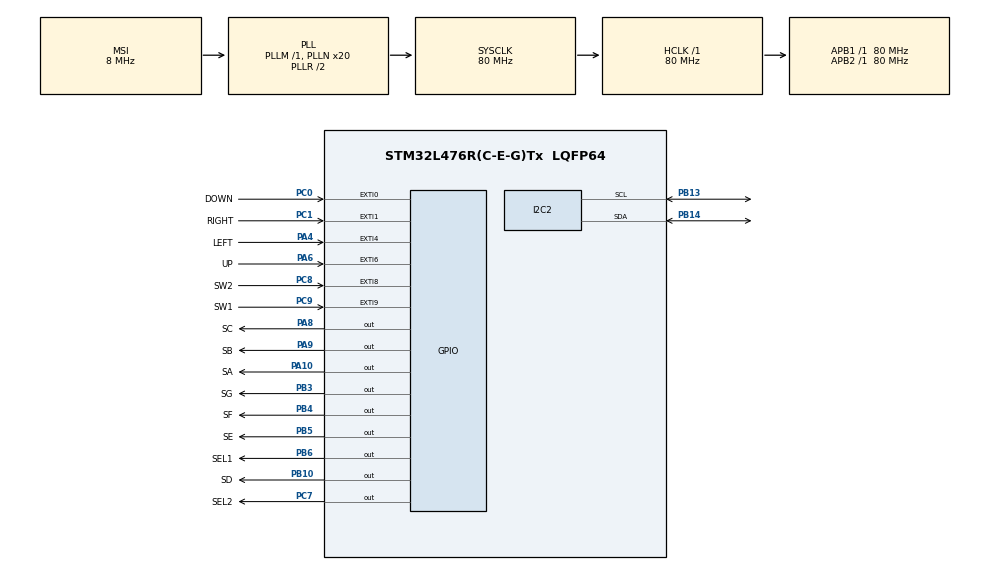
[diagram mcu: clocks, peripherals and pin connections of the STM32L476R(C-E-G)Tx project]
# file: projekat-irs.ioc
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FREERTOS.Tasks01=defaultTask,0,128,StartDefaultTask,Default,NULL,Dynamic,NULL,NULL
FREERTOS.configUSE_TIMERS=1
I2C2.Timing=0x10909CEC
Mcu.Family=STM32L4
Mcu.Name=STM32L476R(C-E-G)Tx
Mcu.Package=LQFP64
NVIC.EXTI0_IRQn=true\:5\:0\:false\:false\:true\:true\:true\:true\:true
NVIC.EXTI1_IRQn=true\:5\:0\:false\:false\:true\:true\:true\:true\:true
NVIC.EXTI4_IRQn=true\:5\:0\:false\:false\:true\:true\:true\:true\:true
NVIC.EXTI9_5_IRQn=true\:5\:0\:false\:false\:true\:false\:true\:true\:true
NVIC.PriorityGroup=NVIC_PRIORITYGROUP_4
PA10.GPIO_Label=SA
PA10.Signal=GPIO_Output
PA11.Signal=S_TIM1_CH4
PA4.GPIO_Label=LEFT
PA4.GPIO_ModeDefaultEXTI=GPIO_MODE_IT_FALLING
PA4.GPIO_PuPd=GPIO_PULLUP
PA4.Signal=GPXTI4
PA6.GPIO_Label=UP
PA6.GPIO_ModeDefaultEXTI=GPIO_MODE_IT_FALLING
PA6.GPIO_PuPd=GPIO_PULLUP
PA6.Signal=GPXTI6
PA8.GPIO_Label=SC
PA8.Signal=GPIO_Output
PA9.GPIO_Label=SB
PA9.Signal=GPIO_Output
PB10.GPIO_Label=SD
PB10.Signal=GPIO_Output
PB13.Mode=I2C
PB13.Signal=I2C2_SCL
PB14.Mode=I2C
PB14.Signal=I2C2_SDA
PB3\ (JTDO-TRACESWO).GPIO_Label=SG
PB3\ (JTDO-TRACESWO).Signal=GPIO_Output
PB4\ (NJTRST).GPIO_Label=SF
PB4\ (NJTRST).Signal=GPIO_Output
PB5.GPIO_Label=SE
PB5.Signal=GPIO_Output
PB6.GPIO_Label=SEL1
PB6.Signal=GPIO_Output
PC0.GPIO_Label=DOWN
PC0.GPIO_ModeDefaultEXTI=GPIO_MODE_IT_FALLING
PC0.GPIO_PuPd=GPIO_PULLUP
PC0.Signal=GPXTI0
PC1.GPIO_Label=RIGHT
PC1.GPIO_ModeDefaultEXTI=GPIO_MODE_IT_FALLING
PC1.GPIO_PuPd=GPIO_PULLUP
PC1.Signal=GPXTI1
PC7.GPIO_Label=SEL2
PC7.Signal=GPIO_Output
PC8.GPIO_Label=SW2
PC8.Signal=GPXTI8
PC9.GPIO_Label=SW1
PC9.GPIO_ModeDefaultEXTI=GPIO_MODE_IT_FALLING
PC9.Signal=GPXTI9
ProjectManager.HeapSize=0x200
ProjectManager.StackSize=0x400
ProjectManager.TargetToolchain=STM32CubeIDE
RCC.ADCFreq_Value=32000000
RCC.AHBFreq_Value=80000000
RCC.APB1Freq_Value=80000000
RCC.APB1TimFreq_Value=80000000
RCC.APB2Freq_Value=80000000
RCC.APB2TimFreq_Value=80000000
RCC.CortexFreq_Value=80000000
RCC.HCLKFreq_Value=80000000
RCC.HSE_VALUE=8000000
RCC.HSI_VALUE=16000000
RCC.LSE_VALUE=32768
RCC.MSIClockRange=RCC_MSIRANGE_7
RCC.MSI_VALUE=8000000
RCC.PLLN=20
RCC.SYSCLKFreq_VALUE=80000000
RCC.SYSCLKSource=RCC_SYSCLKSOURCE_PLLCLK
RCC.USBFreq_Value=32000000
RCC.VCOOutputFreq_Value=160000000
SH.S_TIM1_CH4.0=TIM1_CH4
VP_FREERTOS_VS_CMSIS_V1.Mode=CMSIS_V1
board=custom

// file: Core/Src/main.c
/* USER CODE BEGIN Header */
/**
  ******************************************************************************
  * @file           : main.c
  * @brief          : Main program body
  ******************************************************************************
  * @attention
  *
  * Copyright (c) 2022 STMicroelectronics.
  * All rights reserved.
  *
  * This software is licensed under terms that can be found in the LICENSE file
  * in the root directory of this software component.
  * If no LICENSE file comes with this software, it is provided AS-IS.
  *
  ******************************************************************************
  */
/* USER CODE END Header */
#include "main.h"
#include "cmsis_os.h"

/* USER CODE BEGIN Includes */
#include "project-irs2.h"
/* USER CODE END Includes */

I2C_HandleTypeDef hi2c2;

osThreadId defaultTaskHandle;

void SystemClock_Config(void);
static void MX_GPIO_Init(void);
static void MX_I2C2_Init(void);
void StartDefaultTask(void const * argument);

int main(void)
{

  /* MCU Configuration--------------------------------------------------------*/

  /* Reset of all peripherals, Initializes the Flash interface and the Systick. */
  HAL_Init();

  /* Configure the system clock */
  SystemClock_Config();

  /* Initialize all configured peripherals */
  MX_GPIO_Init();
  MX_I2C2_Init();
  /* USER CODE BEGIN 2 */
  project_main();
  /* USER CODE END 2 */

  /* Create the thread(s) */
  /* definition and creation of defaultTask */
  osThreadDef(defaultTask, StartDefaultTask, osPriorityNormal, 0, 128);
  defaultTaskHandle = osThreadCreate(osThread(defaultTask), NULL);

  /* Start scheduler */
  osKernelStart();

  /* We should never get here as control is now taken by the scheduler */
  /* Infinite loop */
  while (1)
  {

  }
}

void SystemClock_Config(void)
{
  RCC_OscInitTypeDef RCC_OscInitStruct = {0};
  RCC_ClkInitTypeDef RCC_ClkInitStruct = {0};

  /** Configure the main internal regulator output voltage
  */
  if (HAL_PWREx_ControlVoltageScaling(PWR_REGULATOR_VOLTAGE_SCALE1) != HAL_OK)
  {
    Error_Handler();
  }

  /** Initializes the RCC Oscillators according to the specified parameters
  * in the RCC_OscInitTypeDef structure.
  */
  RCC_OscInitStruct.OscillatorType = RCC_OSCILLATORTYPE_MSI;
  RCC_OscInitStruct.MSIState = RCC_MSI_ON;
  RCC_OscInitStruct.MSICalibrationValue = 0;
  RCC_OscInitStruct.MSIClockRange = RCC_MSIRANGE_7;
  RCC_OscInitStruct.PLL.PLLState = RCC_PLL_ON;
  RCC_OscInitStruct.PLL.PLLSource = RCC_PLLSOURCE_MSI;
  RCC_OscInitStruct.PLL.PLLM = 1;
  RCC_OscInitStruct.PLL.PLLN = 20;
  RCC_OscInitStruct.PLL.PLLP = RCC_PLLP_DIV7;
  RCC_OscInitStruct.PLL.PLLQ = RCC_PLLQ_DIV2;
  RCC_OscInitStruct.PLL.PLLR = RCC_PLLR_DIV2;
  if (HAL_RCC_OscConfig(&RCC_OscInitStruct) != HAL_OK)
  {
    Error_Handler();
  }

  /** Initializes the CPU, AHB and APB buses clocks
  */
  RCC_ClkInitStruct.ClockType = RCC_CLOCKTYPE_HCLK|RCC_CLOCKTYPE_SYSCLK
                              |RCC_CLOCKTYPE_PCLK1|RCC_CLOCKTYPE_PCLK2;
  RCC_ClkInitStruct.SYSCLKSource = RCC_SYSCLKSOURCE_PLLCLK;
  RCC_ClkInitStruct.AHBCLKDivider = RCC_SYSCLK_DIV1;
  RCC_ClkInitStruct.APB1CLKDivider = RCC_HCLK_DIV1;
  RCC_ClkInitStruct.APB2CLKDivider = RCC_HCLK_DIV1;

  if (HAL_RCC_ClockConfig(&RCC_ClkInitStruct, FLASH_LATENCY_4) != HAL_OK)
  {
    Error_Handler();
  }
}

static void MX_I2C2_Init(void)
{

  hi2c2.Instance = I2C2;
  hi2c2.Init.Timing = 0x10909CEC;
  hi2c2.Init.OwnAddress1 = 0;
  hi2c2.Init.AddressingMode = I2C_ADDRESSINGMODE_7BIT;
  hi2c2.Init.DualAddressMode = I2C_DUALADDRESS_DISABLE;
  hi2c2.Init.OwnAddress2 = 0;
  hi2c2.Init.OwnAddress2Masks = I2C_OA2_NOMASK;
  hi2c2.Init.GeneralCallMode = I2C_GENERALCALL_DISABLE;
  hi2c2.Init.NoStretchMode = I2C_NOSTRETCH_DISABLE;
  if (HAL_I2C_Init(&hi2c2) != HAL_OK)
  {
    Error_Handler();
  }

  /** Configure Analogue filter
  */
  if (HAL_I2CEx_ConfigAnalogFilter(&hi2c2, I2C_ANALOGFILTER_ENABLE) != HAL_OK)
  {
    Error_Handler();
  }

  /** Configure Digital filter
  */
  if (HAL_I2CEx_ConfigDigitalFilter(&hi2c2, 0) != HAL_OK)
  {
    Error_Handler();
  }

}

static void MX_GPIO_Init(void)
{
  GPIO_InitTypeDef GPIO_InitStruct = {0};

  /* GPIO Ports Clock Enable */
  __HAL_RCC_GPIOC_CLK_ENABLE();
  __HAL_RCC_GPIOA_CLK_ENABLE();
  __HAL_RCC_GPIOB_CLK_ENABLE();

  /*Configure GPIO pin Output Level */
  HAL_GPIO_WritePin(GPIOB, SD_Pin|SG_Pin|SF_Pin|SE_Pin
                          |SEL1_Pin, GPIO_PIN_RESET);

  /*Configure GPIO pin Output Level */
  HAL_GPIO_WritePin(SEL2_GPIO_Port, SEL2_Pin, GPIO_PIN_RESET);

  /*Configure GPIO pin Output Level */
  HAL_GPIO_WritePin(GPIOA, SC_Pin|SB_Pin|SA_Pin, GPIO_PIN_RESET);

  /*Configure GPIO pins : DOWN_Pin RIGHT_Pin */
  GPIO_InitStruct.Pin = DOWN_Pin|RIGHT_Pin;
  GPIO_InitStruct.Mode = GPIO_MODE_IT_FALLING;
  GPIO_InitStruct.Pull = GPIO_PULLUP;
  HAL_GPIO_Init(GPIOC, &GPIO_InitStruct);

  /*Configure GPIO pins : LEFT_Pin UP_Pin */
  GPIO_InitStruct.Pin = LEFT_Pin|UP_Pin;
  GPIO_InitStruct.Mode = GPIO_MODE_IT_FALLING;
  GPIO_InitStruct.Pull = GPIO_PULLUP;
  HAL_GPIO_Init(GPIOA, &GPIO_InitStruct);

  /*Configure GPIO pins : SD_Pin SG_Pin SF_Pin SE_Pin
                           SEL1_Pin */
  GPIO_InitStruct.Pin = SD_Pin|SG_Pin|SF_Pin|SE_Pin
                          |SEL1_Pin;
  GPIO_InitStruct.Mode = GPIO_MODE_OUTPUT_PP;
  GPIO_InitStruct.Pull = GPIO_NOPULL;
  GPIO_InitStruct.Speed = GPIO_SPEED_FREQ_LOW;
  HAL_GPIO_Init(GPIOB, &GPIO_InitStruct);

  /*Configure GPIO pin : SEL2_Pin */
  GPIO_InitStruct.Pin = SEL2_Pin;
  GPIO_InitStruct.Mode = GPIO_MODE_OUTPUT_PP;
  GPIO_InitStruct.Pull = GPIO_NOPULL;
  GPIO_InitStruct.Speed = GPIO_SPEED_FREQ_LOW;
  HAL_GPIO_Init(SEL2_GPIO_Port, &GPIO_InitStruct);

  /*Configure GPIO pin : SW2_Pin */
  GPIO_InitStruct.Pin = SW2_Pin;
  GPIO_InitStruct.Mode = GPIO_MODE_IT_RISING;
  GPIO_InitStruct.Pull = GPIO_NOPULL;
  HAL_GPIO_Init(SW2_GPIO_Port, &GPIO_InitStruct);

  /*Configure GPIO pin : SW1_Pin */
  GPIO_InitStruct.Pin = SW1_Pin;
  GPIO_InitStruct.Mode = GPIO_MODE_IT_FALLING;
  GPIO_InitStruct.Pull = GPIO_NOPULL;
  HAL_GPIO_Init(SW1_GPIO_Port, &GPIO_InitStruct);

  /*Configure GPIO pins : SC_Pin SB_Pin SA_Pin */
  GPIO_InitStruct.Pin = SC_Pin|SB_Pin|SA_Pin;
  GPIO_InitStruct.Mode = GPIO_MODE_OUTPUT_PP;
  GPIO_InitStruct.Pull = GPIO_NOPULL;
  GPIO_InitStruct.Speed = GPIO_SPEED_FREQ_LOW;
  HAL_GPIO_Init(GPIOA, &GPIO_InitStruct);

  /*Configure GPIO pin : PA11 */
  GPIO_InitStruct.Pin = GPIO_PIN_11;
  GPIO_InitStruct.Mode = GPIO_MODE_AF_PP;
  GPIO_InitStruct.Pull = GPIO_NOPULL;
  GPIO_InitStruct.Speed = GPIO_SPEED_FREQ_LOW;
  GPIO_InitStruct.Alternate = GPIO_AF1_TIM1;
  HAL_GPIO_Init(GPIOA, &GPIO_InitStruct);

  /* EXTI interrupt init*/
  HAL_NVIC_SetPriority(EXTI0_IRQn, 5, 0);
  HAL_NVIC_EnableIRQ(EXTI0_IRQn);

  HAL_NVIC_SetPriority(EXTI1_IRQn, 5, 0);
  HAL_NVIC_EnableIRQ(EXTI1_IRQn);

  HAL_NVIC_SetPriority(EXTI4_IRQn, 5, 0);
  HAL_NVIC_EnableIRQ(EXTI4_IRQn);

  HAL_NVIC_SetPriority(EXTI9_5_IRQn, 5, 0);
  HAL_NVIC_EnableIRQ(EXTI9_5_IRQn);

}

void StartDefaultTask(void const * argument)
{
  for(;;)
  {
    osDelay(1);
  }
}

void Error_Handler(void)
{
  __disable_irq();
  while (1)
  {
  }
}
